# rCSL_usb_otg_001 register map
Vendor: Texas Instruments
Peripheral module from a debugger description file (folder c674x).
Registers are 32-bit, read-write, reset 0x0 unless marked. A register's access mark holds for its fields unless they carry their own. Offsets are as the file gives them; lines under a group give offsets from that group; [hi:lo] are bit positions; {n}, {i} and the like mark numbered series; 'fields as' and 'values as' point back to an identical list; <NAME> marks a mode.

## usb_otg — USB 2.0 OTG Controller with CPPI4.1 DMA Engine
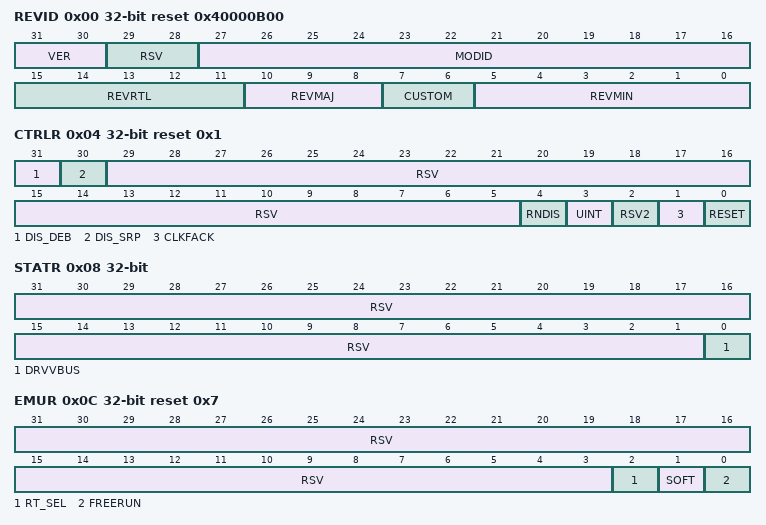
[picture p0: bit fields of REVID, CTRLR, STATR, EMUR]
0x00 REVID ro reset 0x40000B00 (reset mask 0xF000FFFF) — Revision Register
  [31:30] VER — Revision Register Version
  [29:28] RSV — Reserved
  [27:16] MODID — Module ID
  [15:11] REVRTL — RTL Revision
  [10:8] REVMAJ — Major Revision
  [7:6] CUSTOM — Custom Revision
  [5:0] REVMIN — Minor Revision
0x04 CTRLR access per field reset 0x1 — Control Register
  [31] DIS_DEB rw — Disable VBUS Debounce Fix
  [30] DIS_SRP rw — Disable SRP a_valid circuit fix
  [29:5] RSV ro — Reserved
  [4] RNDIS rw — Global RNDIS Mode Enable for All Endpoints
  [3] UINT rw — USB non-PDR Interrupt Enable
  [2] RSV2 ro — Reserved
  [1] CLKFACK rw — Clock Stop Fast Acknowledge
  [0] RESET rw — Soft Reset
0x08 STATR ro — Status Register
  [31:1] RSV — Reserved
  [0] DRVVBUS — Current DRVVBUS Value
0x0C EMUR access per field reset 0x7 — Emulation Register
  [31:3] RSV ro — Reserved
  [2] RT_SEL rw — Real Time Enable
  [1] SOFT rw — Soft Stop Enable
  [0] FREERUN rw — Free Run Enable
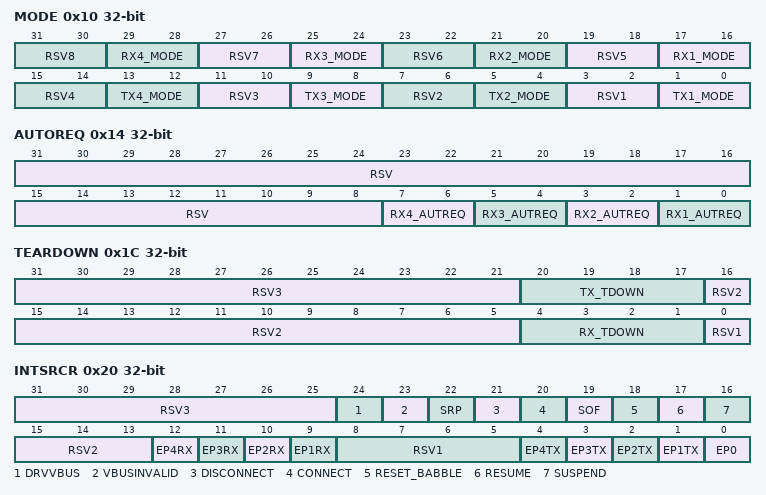
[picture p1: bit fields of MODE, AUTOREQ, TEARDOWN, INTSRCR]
0x10 MODE access per field — RNDIS MODE REGISTER
  [4n-1:4n-2] RSV{n} ro (n=1..8) — Reserved
  [4n+13:4n+12] RX{n}_MODE rw (n=1..4) — RX Endpoint {n} Mode
    0=TRANSPARENT (Transparent Mode); 1=RNDIS (RNDIS Mode); 2=CDC (Linux CDC Mode); 3=GENRNDIS (Generic RNDIS Mode)
  [4n-3:4n-4] TX{n}_MODE rw (n=1..4) — TX Endpoint {n} Mode
    values as RX1_MODE
0x14 AUTOREQ access per field — Auto Request Register
  [31:8] RSV ro — Reserved
  [2n-1:2n-2] RX{n}_AUTREQ rw (n=1..4) — RX{n} Autorequest Enable
    0=NONE (No Auto Req); 1=ALL_BUT_EOP (Auto Req All but EOP); 3=ALL (Auto Req Always)
0x18 SRPFIXTIME reset 0x42000000
  [31:0] SRPFIXTIME — SRP Fix maximum time in 60 MHz cycles. Default is 700ms.
0x1C TEARDOWN access per field
  [31:21] RSV3 ro — Reserved
  [20:17] TX_TDOWN rw — Tx Endpoint Teardown.
    8=TX4 (Teardown TX4 Endpoint); 4=TX3 (Teardown TX3 Endpoint); 2=TX2 (Teardown TX2 Endpoint); 1=TX1 (Teardown TX1 Endpoint)
  [16:5] RSV2 ro — Reserved
  [4:1] RX_TDOWN rw — Rx Endpoint Teardown.
    8=RX4 (Teardown RX4 Endpoint); 4=RX3 (Teardown RX3 Endpoint); 2=RX2 (Teardown RX2 Endpoint); 1=RX1 (Teardown RX1 Endpoint)
  [0] RSV1 ro — Reserved
0x20 INTSRCR ro — USB Interrupt Source Register
  [31:25] RSV3 — Reserved
  [24] DRVVBUS — DRVVBUS Level Change
  [23] VBUSINVALID — VBUS lessthan VBUS Valid
  [22] SRP — SRP Detected
  [21] DISCONNECT — Device Disconnected
  [20] CONNECT — Device Connected
  [19] SOF — SOF Started
  [18] RESET_BABBLE — RESET Signalling Detected (Peripheral Mode) or Babble Detected (Host Mode)
  [17] RESUME — RESUME Signalling Detected
  [16] SUSPEND — SUSPEND Signalling Detected
  [15:13] RSV2 — Reserved
  [n+8] EP{n}RX (n=1..4) — Endpoint {n} RX Interrupt Status
  [8:5] RSV1 — Reserved
  [n] EP{n}TX (n=1..4) — Endpoint {n} TX Interrupt Status
  [0] EP0 — Endpoint 0 Interrupt Status
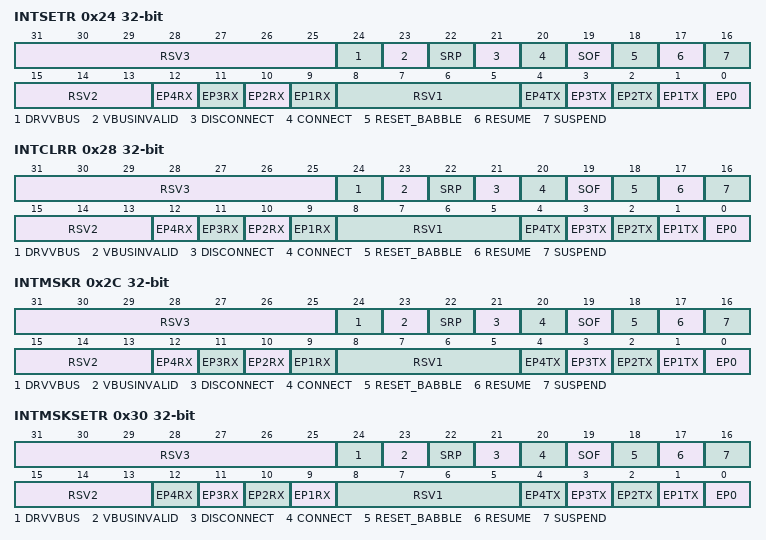
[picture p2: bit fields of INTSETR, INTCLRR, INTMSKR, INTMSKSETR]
0x24 INTSETR access per field — USB Interrupt Source Set Register
  [31:25] RSV3 ro — Reserved
  [24] DRVVBUS wo — DRVVBUS Level Change Interrupt Set
  [23] VBUSINVALID wo — VBUS lessthan VBUS Valid Interrupt Set
  [22] SRP wo — SRP Detected Interrupt Set
  [21] DISCONNECT wo — Device Disconnected Interrupt Set
  [20] CONNECT wo — Device Connected Interrupt Set
  [19] SOF wo — SOF Started Interrupt Set
  [18] RESET_BABBLE wo — RESET Signalling Detected (Peripheral Mode) or Babble Detected (Host Mode) Interrupt Set
  [17] RESUME wo — RESUME Signalling Detected Interrupt Set
  [16] SUSPEND wo — SUSPEND Signalling Detected Interrupt Set
  [15:13] RSV2 ro — Reserved
  [n+8] EP{n}RX wo (n=1..4) — Endpoint {n} RX Interrupt Status Set
  [8:5] RSV1 ro — Reserved
  [n] EP{n}TX wo (n=1..4) — Endpoint {n} TX Interrupt Status Set
  [0] EP0 wo — Endpoint 0 Interrupt Status Set
0x28 INTCLRR access per field — USB Interrupt Source Clear Register
  [31:25] RSV3 ro — Reserved
  [24] DRVVBUS wo — DRVVBUS Level Change Interrupt Set
  [23] VBUSINVALID wo — VBUS lessthan VBUS Valid Interrupt Clear
  [22] SRP wo — SRP Detected Interrupt Clear
  [21] DISCONNECT wo — Device Disconnected Interrupt Clear
  [20] CONNECT wo — Device Connected Interrupt Clear
  [19] SOF wo — SOF Started Interrupt Clear
  [18] RESET_BABBLE wo — RESET Signalling Detected (Peripheral Mode) or Babble Detected (Host Mode) Interrupt Clear
  [17] RESUME wo — RESUME Signalling Detected Interrupt Clear
  [16] SUSPEND wo — SUSPEND Signalling Detected Interrupt Clear
  [15:13] RSV2 ro — Reserved
  [n+8] EP{n}RX wo (n=1..4) — Endpoint {n} RX Interrupt Status Clear
  [8:5] RSV1 ro — Reserved
  [n] EP{n}TX wo (n=1..4) — Endpoint {n} TX Interrupt Status Clear
  [0] EP0 wo — Endpoint 0 Interrupt Status Clear
0x2C INTMSKR ro — USB Interrupt Mask Register
  fields as INTSRCR
0x30 INTMSKSETR access per field — USB Interruppt Mask Set Register
  [31:25] RSV3 ro — Reserved
  [24] DRVVBUS wo — DRVVBUS Level Change Interrupt Mask Set
  [23] VBUSINVALID wo — VBUS lessthan VBUS Valid Interrupt Mask Set
  [22] SRP wo — SRP Detected Interrupt Mask Set
  [21] DISCONNECT wo — Device Disconnected Interrupt Mask Set
  [20] CONNECT wo — Device Connected Interrupt Mask Set
  [19] SOF wo — SOF Started Interrupt Mask Set
  [18] RESET_BABBLE wo — RESET Signalling Detected (Peripheral Mode) or Babble Detected (Host Mode) Interrupt Mask Set
  [17] RESUME wo — RESUME Signalling Detected Interrupt Mask Set
  [16] SUSPEND wo — SUSPEND Signalling Detected Interrupt Mask Set
  [15:13] RSV2 ro — Reserved
  [12] EP4RX wo — Endpoint 4 RX Interrupt Status Mask Set
  [11] EP3RX wo — Endpoint 3 RX Interrupt Mask Set
  [10] EP2RX wo — Endpoint 2 RX Interrupt Mask Set
  [9] EP1RX wo — Endpoint 1 RX Interrupt Mask Set
  [8:5] RSV1 ro — Reserved
  [n] EP{n}TX wo (n=1..4) — Endpoint {n} TX Interrupt Mask Set
  [0] EP0 wo — Endpoint 0 Interrupt Mask Set
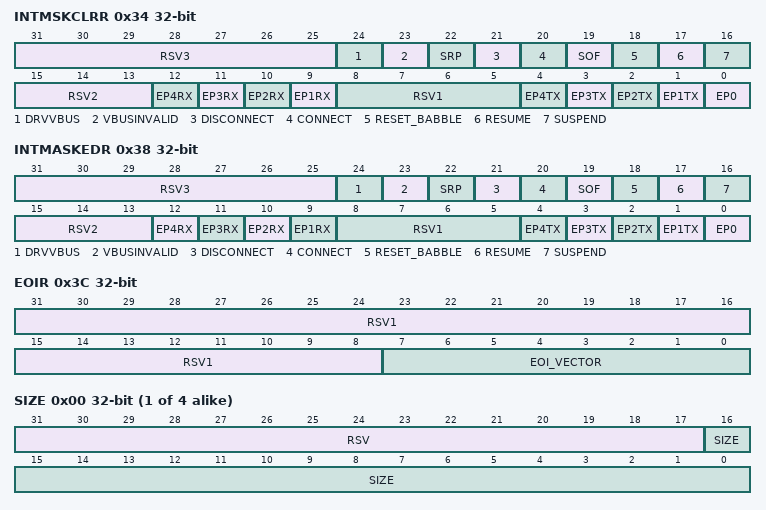
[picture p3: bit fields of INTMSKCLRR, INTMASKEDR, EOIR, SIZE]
0x34 INTMSKCLRR access per field — USB Interruppt Mask Clear Register
  [31:25] RSV3 ro — Reserved
  [24] DRVVBUS wo — DRVVBUS Level Change Interrupt Mask Clear
  [23] VBUSINVALID wo — VBUS lessthan VBUS Valid Interrupt Mask Clear
  [22] SRP wo — SRP Detected Interrupt Mask Clear
  [21] DISCONNECT wo — Device Disconnected Interrupt Mask Clear
  [20] CONNECT wo — Device Connected Interrupt Mask Clear
  [19] SOF wo — SOF Started Interrupt Mask Clear
  [18] RESET_BABBLE wo — RESET Signalling Detected (Peripheral Mode) or Babble Detected (Host Mode) Interrupt Mask Clear
  [17] RESUME wo — RESUME Signalling Detected Interrupt Mask Clear
  [16] SUSPEND wo — SUSPEND Signalling Detected Interrupt Mask Clear
  [15:13] RSV2 ro — Reserved
  [12] EP4RX wo — Endpoint 4 RX Interrupt Status Mask Clear
  [11] EP3RX wo — Endpoint 3 RX Interrupt Mask Clear
  [10] EP2RX wo — Endpoint 2 RX Interrupt Mask Clear
  [9] EP1RX wo — Endpoint 1 RX Interrupt Mask Clear
  [8:5] RSV1 ro — Reserved
  [n] EP{n}TX wo (n=1..4) — Endpoint {n} TX Interrupt Mask Clear
  [0] EP0 wo — Endpoint 0 Interrupt Mask Clear
0x38 INTMASKEDR ro — USB Interrupt Source Masked Register
  fields as INTSRCR
0x3C EOIR access per field — USB End Of Interrupt
  [31:8] RSV1 ro — Reserved
  [7:0] EOI_VECTOR rw
0x40 INTVECTR — USB Interrupt Vector
  [31:0] VECTOR — Interrupt Vector
{0x80+4i} GENRNDISSZ[{i}] (i=0..3) group — RNDIS REGISTERS
  0x00 SIZE access per field — Generic RNDIS Size
    [31:17] RSV ro — Reserved
    [16:0] SIZE rw — Generic RNDIS Packet Size
0x400 FADDR 8-bit — Function Address
  [6:0] FUNCADDR
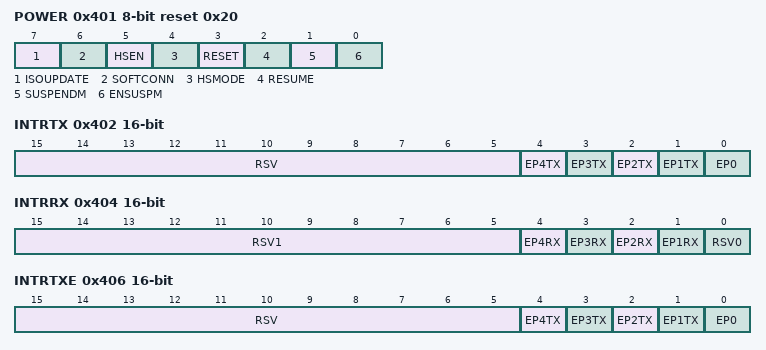
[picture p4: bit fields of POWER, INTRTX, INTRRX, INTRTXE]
0x401 POWER 8-bit access per field reset 0x20 — Power Management Register
  [7] ISOUPDATE rw — Isoc Update
  [6] SOFTCONN rw — Soft Connect/Disconnect - Enables the D+/D- lines when set. Only valid in peripheral mode.
  [5] HSEN rw — When set, the device will negotiate for High speed mode when reset by the hub.
  [4] HSMODE ro — Valid when usb reset completes (peripheral mode) or when Reset bit is cleared (host mode). When set it indicates that the device sucessfully negotiated high speed mode.
  [3] RESET rw — USB Bus Reset: Host mode Read/Write. Peripheral Mode Read Only
  [2] RESUME rw — Set byt the CPU to generate resume signaling when the function is in suspend mode. Automatically set in host mode when Resume signalling from the target is detected and the host is suspended.
  [1] SUSPENDM rw — In host mode, set by the CPU to enter SUSPEND mode. In peripheral mode, this bit is set on entry into SUSPEND mode.
  [0] ENSUSPM rw — Set by the CPU to enable the SUSPENDM signal.
0x402 INTRTX 16-bit ro — Transmit Endpoint Interrupt Register
  [15:5] RSV — Reserved
  [n] EP{n}TX (n=1..4) — EP{n} TX Interrupt
  [0] EP0 — EP0 Interrupt
0x404 INTRRX 16-bit ro — Transmit Endpoint Interrupt Register
  [15:5] RSV1 — Reserved
  [n] EP{n}RX (n=1..4) — EP{n} RX Interrupt
  [0] RSV0 — Reserved
0x406 INTRTXE 16-bit access per field — Transmit Endpoint Interrupt Enable Register
  [15:5] RSV ro — Reserved
  [n] EP{n}TX rw (n=1..4) — EP{n} TX Interrupt
  [0] EP0 rw — EP0 Interrupt
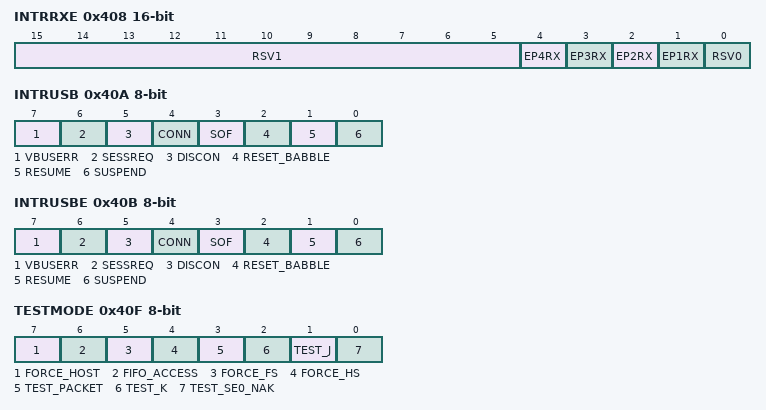
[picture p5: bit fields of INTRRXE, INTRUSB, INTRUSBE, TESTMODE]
0x408 INTRRXE 16-bit access per field — Transmit Endpoint Interrupt Enable Register
  [15:5] RSV1 ro — Reserved
  [n] EP{n}RX rw (n=1..4) — EP{n} RX Interrupt
  [0] RSV0 rw — Reserved
0x40A INTRUSB 8-bit ro — USB Bus Interrupts
  [7] VBUSERR — VBUS lessthan VBUS Valid
  [6] SESSREQ — SRP Detected
  [5] DISCON — Device Disconnected
  [4] CONN — Device Connected
  [3] SOF — SOF Started
  [2] RESET_BABBLE — RESET Signalling Detected (Peripheral Mode) or Babble Detected (Host Mode)
  [1] RESUME — RESUME Signalling Detected
  [0] SUSPEND — SUSPEND Signalling Detected
0x40B INTRUSBE 8-bit — USB Interrupt Enable Register
  fields as INTRUSB
0x40C FRAME 16-bit ro — Frame Number of Last Received Frame
  [10:0] FRAMENUMBER
0x40E INDEX 8-bit — Selects Endpoint accessed through index register
  [3:0] EPSEL — Endpoint Selection Index
    0=EP0; {v}=EP{v} (v=0..4)
0x40F TESTMODE 8-bit
  [7] FORCE_HOST, [6] FIFO_ACCESS, [5] FORCE_FS, [4] FORCE_HS, [3] TEST_PACKET, [2] TEST_K, [1] TEST_J, [0] TEST_SE0_NAK
0x410 TXMAXP 16-bit — Max Packet Size for Transmit Packet
  [10:0] MAXPAYLOAD
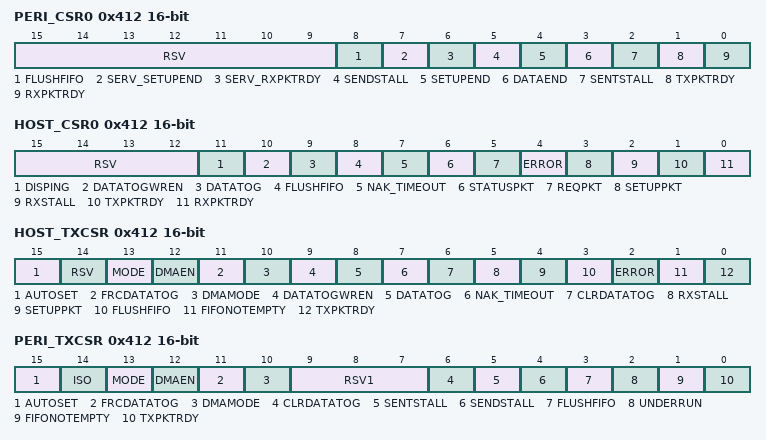
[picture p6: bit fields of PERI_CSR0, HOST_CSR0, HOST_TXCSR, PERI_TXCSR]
0x412 PERI_CSR0 16-bit access per field — TRANSMIT / ENDPOINT 0 CONTROL AND STATUS IN PERIPHERAL MODE
  [15:9] RSV ro — Reserved
  [8] FLUSHFIFO rw — Write a 1 to this bit to flush the enxt packet to be transmitted/read from the Endpoint0 FIFO. The FIFO pointer is reset and the TXPKTRDY/RXPKTRDY bit is cleared.
  [7] SERV_SETUPEND rw — Write 1 to Clear SetupEnd bit.
  [6] SERV_RXPKTRDY rw — Write 1 to clear RXPKTRDY bit.
  [5] SENDSTALL rw — Write 1 to terminate the current transaction
  [4] SETUPEND rw — This bit will be set when a control transaction ends before the DataEnd bit has been set. An interrupt will be generated and the FIFO flushed at this time. The bit is cleared by the CPU writing a 1 to the SERVICED_SETUP_END bit
  [3] DATAEND rw
  [2] SENTSTALL rw — This bit is set when a STALL handshake is transmitted. The CPU should clear this bit
  [1] TXPKTRDY rw — The CPU sets this bit after loading a data packet into the FIFO. It is cleared automatically when the data packet has been transmitted. An interrupt is generated (if enabled) when this bit is cleared.
  [0] RXPKTRDY rw — This bit is set when a data packet has been received. An interrupt is generated when this bit is set. The CPU clears this bit by setting the SERVICED_RXPKTRDY bit.
0x412 HOST_CSR0 16-bit access per field — TRANSMIT / ENDPOINT 0 CONTROL AND STATUS IN HOST MODE
  [15:12] RSV ro — Reserved
  [11] DISPING rw — The CPU writes a 1 to this bit to instruct the core not to issue PING tokens in data and status phases of a high-speed Control transfer (For use with devices that do not respond to PING)
  [10] DATATOGWREN rw — The CPU writes a 1 to this bit to enable the current state of the Endpoint 0 data toggle to be written. This bit is automatically cleared once the new value is written.
  [9] DATATOG rw — When read, this bit indicates the current state of the Endpoint 0 data toggle. If D10 is high, this bit may bw written with the required setting of the data toggle. If D10 is low, any value written to this bit is ignored.
  [8] FLUSHFIFO rw — The CPU writes a 1 to this bit to flush the next packet to be transmitted/read from the Endpoint 0 FIFO. The FIFO pointer is reset and the TXPKTRDY/RXPKTRDY bit(Below) is cleared. Note: FlushFIFO should only be used when TXPKTRDY/RXPKTRDY is SET. At other times it may cause data to be corrupted.
  [7] NAK_TIMEOUT rw — This bit will be set when Endpoint 0 is halted following the receipt of NAK responses for longer than the time set by the NAKLimit0 register. The CPU should clear this bit to allow the endpoint to continue.
  [6] STATUSPKT rw — The CPU sets this bit at the same time as the TXPKTRDY or REQPKT bit is set, to perform a status stage transaction. Setting this bit ensures that the data toggle is set to 1 so that a DATA1 packet is used for the Status Stage transaction.
  [5] REQPKT rw — The CPU sets this bit to request an IN transaction. It is cleared when the RXPKTRDY is set.
  [4] ERROR rw — This bit will be set when a control transaction ends before the DataEnd bit has been set. An interrupt will be generated and the FIFO flushed at this time. The bit is cleared by the CPU writing a 1 to the SERVICED_SETUP_END bit
  [3] SETUPPKT rw — The CPU sets this bit, at the same time as the TXPKTRDY bit is set to send a SETUP token instead of an OUT token for the transaction. Note: Setting this bit also clears the data toggle.
  [2] RXSTALL rw — This bit is set when a STALL handshake is received. The CPU should clear this bit
  [1] TXPKTRDY rw — The CPU sets this bit after loading a data packet into the FIFO. It is cleared automatically when the data packet has been transmitted. An interrupt is generated (if enabled) when this bit is cleared.
  [0] RXPKTRDY rw — This bit is set when a data packet has been received. An interrupt is generated when this bit is set. The CPU clears this bit by setting the SERVICED_RXPKTRDY bit.
0x412 HOST_TXCSR 16-bit access per field — CSR REGISTER FOR TRANSMIT ENDPOINT (INDEXED) - HOST MODE
  [15] AUTOSET rw — If the CPU sets this bit, TXPKTRDY will be automatically set when data of the maximum packet size (Value in TXMAXP) is loaded into the TX FIFO. If a packet of less than the maximum packet size is loaded, then TXPKTRDY will have to be set manually.
  [14] RSV ro — RESERVED - RETURNS 0
  [13] MODE rw — The CPU sets this bit to enable the endpoint direction as TX and clears it to enable the endpoint direction as RX. Only takes effect when the same endpoint FIFO is used for both TX and RX transactions
  [12] DMAEN rw — The CPU sets this bit to enable the DMA request for the TX Endpoint
  [11] FRCDATATOG ro — Reserved
  [10] DMAMODE ro
  [9] DATATOGWREN ro — Reserved
  [8] DATATOG ro — Reserved
  [7] NAK_TIMEOUT ro — Reserved
  [6] CLRDATATOG rw — The CPU writes a 1 to this bit to reset the endpoint data toggle to 0
  [5] RXSTALL rw — This bit is set when a STALL handshake is received. When this bit is set, any DMA request that is in progress is stopped, the FIFO is completely flushed, and the TXPKTRDY bit is cleared. The CPU should clear this bit.
  [4] SETUPPKT rw — The CPU sets this bit, at the same time as the TXPKTRDY bit is set, to send a SETUP token instead of an OUT token for the transaction. Note: Setting this bit also clears the Data Toggle.
  [3] FLUSHFIFO rw — The CPU writes a 1 to this bit to flush the latest packet from the endpoint TX FIFO. The FIFO pointer is reset, the TXPKTRDY bit is cleared and an interrupt is generated. May be set simultanelusly with TXPKTRDY to abort the packet that is currently being loaded into the FIFO. Note: Flush FIFO shoudl onlyb e used when TXPKTRDY is set. At other times, it may cause data to be corrupted. Also note that, if the FIFO is doubled buffered, FLUSH_FIFO may need to be set twice to compltetely clear the FIFO
  [2] ERROR rw — The USB sets this bit when 3 attempts have been made to send a packet and no handshake packet has been received. When the bit is set, and interrupt is generated, TXPKTRDY is cleared, and the FIFO is completely flushed. The CPU should clear this bit. Valid only when the endpoint is operating in Bulk or Interrupt Mode.
  [1] FIFONOTEMPTY rw — The USB sets this bit when there is at least 1 packet in the TX FIFO
  [0] TXPKTRDY rw — The CPU sets this bit after loading a data packet into the FIFO. It is cleared automatically when a data packet has been transmitted. An interrupt is also generated at thsi point (if enabled) TXPKTRDY is also automatically cleared prior to loading a second packet into a double-buffered FIFO
0x412 PERI_TXCSR 16-bit access per field — CSR REGISTER FOR TRANSMIT ENDPOINT (INDEXED) - PERIPHERAL MODE
  [15] AUTOSET rw — If the CPU sets this bit, TXPKTRDY will be automatically set when data of the maximum packet size (Value in TXMAXP) is loaded into the TX FIFO. If a packet of less than the maximum packet size is loaded, then TXPKTRDY will have to be set manually.
  [14] ISO rw — CPU sets this bit to enable the TX Endpoint for Isochronous Transfers, and clears it to enable the TX Endpoint for Bulk or Interrupt Transfers.
  [13] MODE rw — The CPU sets this bit to enable the endpoint direction as TX and clears it to enable the endpoint direction as RX. Only takes effect when the same endpoint FIFO is used for both TX and RX transactions
  [12] DMAEN rw — The CPU sets this bit to enable the DMA request for the TX Endpoint
  [11] FRCDATATOG rw
  [10] DMAMODE rw
  [9:7] RSV1 ro — Reserved
  [6] CLRDATATOG rw — The CPU writes a 1 to this bit to reset the endpoint data toggle to 0
  [5] SENTSTALL rw — This bit is set when a STALL handshake is transmitted. The FIFO is flushed and the TXPKTRDY bit is cleared.
  [4] SENDSTALL rw — The CPU writes a 1 to this bit to issue a STALL handshake to an IN token. The CPU clears this bit to terminate a stall condition
  [3] FLUSHFIFO rw — The CPU writes a 1 to this bit to flush the latest packet from the endpoint TX FIFO. The FIFO pointer is reset, the TXPKTRDY bit is cleared and an interrupt is generated. May be set simultanelusly with TXPKTRDY to abort the packet that is currently being loaded into the FIFO. Note: Flush FIFO shoudl onlyb e used when TXPKTRDY is set. At other times, it may cause data to be corrupted. Also note that, if the FIFO is doubled buffered, FLUSH_FIFO may need to be set twice to compltetely clear the FIFO
  [2] UNDERRUN rw — The USB sets this bit if an IN token is received when the TXPKTRDY bit is not set. The CPU should clear this bit.
  [1] FIFONOTEMPTY rw — The USB sets this bit when there is at least 1 packet in the TX FIFO
  [0] TXPKTRDY rw — The CPU sets this bit after loading a data packet into the FIFO. It is cleared automatically when a data packet has been transmitted. An interrupt is also generated at thsi point (if enabled) TXPKTRDY is also automatically cleared prior to loading a second packet into a double-buffered FIFO
0x414 RXMAXP 16-bit — RX ENDPOINT MAX PACKET SIZE
  [10:0] MAXPAYLOAD
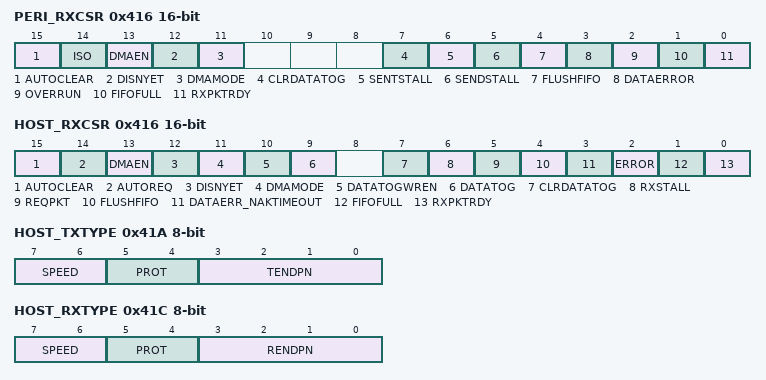
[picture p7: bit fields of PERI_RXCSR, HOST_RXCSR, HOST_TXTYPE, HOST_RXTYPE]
0x416 PERI_RXCSR 16-bit — Receive Control/Status Register Peripheral Mode
  [15] AUTOCLEAR — If the CPU sets this bit then the RXPKTRDY bit will be automatically cleared when a packet of RXMAXP bytes has been unloaded from the RXFIFO. When packets of less than the maximum packet size are unloaded. RXPKTRDY will have to be cleared manually.
  [14] ISO — The CPU sets this bit to enable the RX Endpoint for ISOCHRONOUS transfers and clears it to enable the RX Endpoint for Bulk/Interrupt transfers
  [13] DMAEN — The CPU sets this bit to enable the DMA request for the RX Endpoint
  [12] DISNYET — In bulk and interrupt mode, the CPU sets this bit to disable the sending of a NYET handshake. When set all sucessfully received RX packets are ACK'd including at the point at which the FIFO becomes ful.
  [11] DMAMODE — The CPU sets thsi bit to select DMA Mode 1 and clears this bit to select DMA Mode 0
  [7] CLRDATATOG — The CPU writes a 1 to this bit to reset the endpoint data toggle to 0
  [6] SENTSTALL — This bit is set when a STALL handshake is transmitted. The CPU should clear this bit.
  [5] SENDSTALL — The CPU writes a 1 to this bit to issue a STALL handshake. The CPU clears this bit to terminate the stall condition.
  [4] FLUSHFIFO — The CPU writes a 1 to this bit to flush the next packet to be read from the Endpoint RX FIFO. The FIFO pointer is reset and the RXPKTRDY bit is cleared. Note that if the FIFO is doubled buffered, FIFOFLUSH may need to be set twice to completely clear the FIFO
  [3] DATAERROR — This bit is set if the data packet has a CRC or bit-stuff error. It is cleared when RXPKTRDY is cleared.
  [2] OVERRUN — This bit is set if an OUT packet cannot be loaded into the RX FIFO. THe CPU should clear this bit.
  [1] FIFOFULL — This bit is set when no more packets can be loaded into the RX FIFO
  [0] RXPKTRDY — This bit is set when a data packet has been received. The CPU should clear this bit when the packet has been unloaded from the RX FIFO. An interrupt is generated when the bit is set.
0x416 HOST_RXCSR 16-bit access per field — Receive Control/Status Register Host Mode
  [15] AUTOCLEAR rw — If the CPU sets this bit then the RXPKTRDY bit will be automatically cleared when a packet of RXMAXP bytes has been unloaded from the RXFIFO. When packets of less than the maximum packet size are unloaded. RXPKTRDY will have to be cleared manually.
  [14] AUTOREQ rw — If the CPU sets this bit, the ReqPkt bit will be automatically set when the RXPKTRDY bit is cleared. Note: This bit is automatically cleared when a short packet is received.
  [13] DMAEN rw — The CPU sets this bit to enable the DMA request for the RX Endpoint
  [12] DISNYET rw — ISO TRANSACTIONS ONLY: The core sets this bit to indicate a PID error in the received packet. Ignored in Bulk/Interrupt Transactions.
  [11] DMAMODE rw — The CPU sets this bit to select DMA Mode 1 and clears this bit to select DMA Mode 0
  [10] DATATOGWREN ro — The CPU writes a 1 to this bit to enable the current state of the RX Endpoint Data toggle to be written. This bit is automatically cleared once the new value is written.
  [9] DATATOG ro — When read, this bit indicates the current state of the RX Endpoint Data Toggle. If DATA_TOGGLE_WRITE_ENABLE is '1' then this bit may be written with the required setting of the data toggle. If DATA_TOGGLE_WRITE_ENABLE is low, any value written to this register is ignored.
  [7] CLRDATATOG rw — The CPU writes a 1 to this bit to reset the endpoint data toggle to 0
  [6] RXSTALL rw — When a STALL handshake is received, this bit is set and an interrupt is generated. The CPU should clear this bit.
  [5] REQPKT rw — The CPU writes a 1 to this bit to request an IN transaction. It is cleared when RXPKTRDY is set
  [4] FLUSHFIFO rw — The CPU writes a 1 to this bit to flush the next packet to be read from the Endpoint RX FIFO. The FIFO pointer is reset and the RXPKTRDY bit is cleared. Note that if the FIFO is doubled buffered, FIFOFLUSH may need to be set twice to completely clear the FIFO
  [3] DATAERR_NAKTIMEOUT rw — When operating in ISO mode, this bit is set when RXPKTRDY is set if the data packet has a CRC or bit-stuff error and cleared when the RXPKTRDY is cleared. In bulk mode, this bit will be set when the RX endpoint is halted following the receipt of NAK responses for longer than the time set as the NAK Limit by the RxInterval register. The CPU should celar this bit to allow the endpoint to continue.
  [2] ERROR rw — The USB sets this bit when 3 attempts have been made to receive a packet and no data packet has been received. The CPU should clear this bit. An interrupt is generated when the bit is set. Note: thsi bit is only valid when the TX endpoint is operating in Bulk or Interrupt mode. In ISO mode, it always returns 0
  [1] FIFOFULL rw — This bit is set when no more packets can be loaded into the RX FIFO
  [0] RXPKTRDY rw — This bit is set when a data packet has been received. The CPU should clear this bit when the packet has been unloaded from the RX FIFO. An interrupt is generated when the bit is set.
0x418 COUNT0 16-bit ro — Count0 is a 7 bit read only register that indicates the number of received data bytes in the Endpoint 0 FIFO. The value returned changes as the contents of the FIFO change and is only valid while RXPKTRDY is set.
  [6:0] EP0RXCOUNT
0x418 RXCOUNT 16-bit ro — RX Count is a 13-bit read only register that holds the number of received dtata bytes in the packet currently in line to be read from the RX FIFO. If the packet was transmitted as multiple bulk packets, the number given will be for the combined packet.
  [12:0] EPRXCOUNT
0x41A HOST_TYPE0 8-bit — TYPE0 FOR ENDPOINT 0
  [7:6] SPEED
    1=HS (High Speed); 2=FS (Full Speed); 3=LS (Low Speed)
0x41A HOST_TXTYPE 8-bit — TXTYPE FOR ENDPOINT1,2,3,4
  [7:6] SPEED
    1=HS (High Speed); 2=FS (Full Speed); 3=LS (Low Speed)
  [5:4] PROT
    0=CTRL (Control); 1=ISOC (Isochronous); 2=BULK; 3=INTR (Interrupt)
  [3:0] TENDPN
0x41B HOST_NAKLIMIT0 8-bit — NAKLIMIT0 FOR ENDPOINT 0
  [4:0] EP0NAKLIMIT
0x41B HOST_TXINTERVAL 8-bit — TXINTERVAL FOR ENDPOINT1,2,3,4
  [7:0] POLINTVL_NAKLIMIT
0x41C HOST_RXTYPE 8-bit — RXTYPE FOR ENDPOINT1,2,3,4
  [7:6] SPEED
    1=HS (High Speed); 2=FS (Full Speed); 3=LS (Low Speed)
  [5:4] PROT
    values as HOST_TXTYPE.PROT
  [3:0] RENDPN
0x41D HOST_RXINTERVAL 8-bit — RXINTERVAL FOR ENDPOINT1,2,3,4
  [7:0] POLINTVL_NAKLIMIT
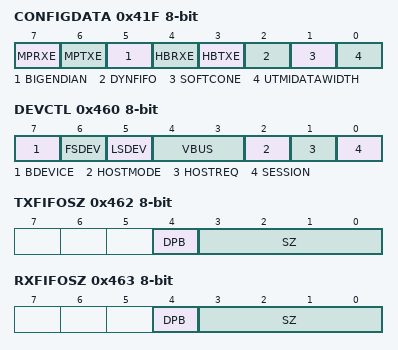
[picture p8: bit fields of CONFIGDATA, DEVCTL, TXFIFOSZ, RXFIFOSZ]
0x41F CONFIGDATA 8-bit ro — Returns details of core configuration for Endpoint 0
  [7] MPRXE — When set to '1' automatic almagamation of bulk packets is selected
  [6] MPTXE — When set to '1' automatic splitting of bulk packets is selected
  [5] BIGENDIAN — When set to '1' Big Endian ordering is selected
  [4] HBRXE — When set to '1' indicates High Badnwidth RX FIFO ISO endpoint support selected
  [3] HBTXE — When set to '1' indicates High Badnwidth TX FIFO ISO endpoint support selected
  [2] DYNFIFO — When set to '1' indicates Dynamic FIFO Sizing option is selected
  [1] SOFTCONE — When set to '1' indicates Soft Connect / Disconnect Option Selected
  [0] UTMIDATAWIDTH — Indicates UTMI+ data width. 0 - 8 bits, 1 - 16 bits
{0x420+4i} FIFO{i} (i=0..4)
  [31:0] DATA — FIFO Data
0x460 DEVCTL 8-bit access per field — OTG Device Control
  [7] BDEVICE ro — THIS READ ONLY BIT INDICATES WHETHER THE DEVICE IS OPERATING AS THE a OR THE b DEVICE.
    0=ADEV (A DEVICE); 1=BDEV (B DEVICE)
  [6] FSDEV ro — THIS READ ONLY BIT INDICATES WHETHER THE DEVICE IS OPERATING IN FULL SPEED OR HIGH SPEED. ONLY VALID IN HOST MODE
    0=HS (high speed); 1=FS (full speed)
  [5] LSDEV ro — THIS READ ONLY BIT INDICATES WHETHER THE DEVICE IS OPERATING IN LOW SPEED. ONLY VALID IN HOST MODE
    0=FS (full speed); 1=LS (low speed)
  [4:3] VBUS ro — THESE READ ONLY BITS ENCODE THE CURRENT VBUS LEVEL
    0=BELOW_SESSION_END (VBUS is below the session End Level); 1=BELOW_AVALID (VBUS is above session End but below AVALID); 2=BELOW_VBUS_VALID (VBUS is above AVALID, but below VBUS Valid); 3=ABOVE_VBUS_VALID (VBUS is above VBUS Valid)
  [2] HOSTMODE ro — This read only bit is set when the USB controller is acting as a HOST
    0=PER_MODE (Peripheral Mode); 1=HOST_MODE
  [1] HOSTREQ rw — When set, the controller will initiate the Host Negotiation Protocol when Suspend mode is entered. It is cleared when Host Negotiation is completed.
    0=HNP_END (HNP Completed); 1=START_HNP (Start Host Negotiation On Suspend Entry)
  [0] SESSION ro — When acting as an "A" device, this bit is set or cleared by the CPU to start or end a session. When operating as a 'b' device, this bit is set/cleared by the controller when a session starts/ends. It is also set by the CPU to initiate the Session Request Protocol. When the controller is in suspend mode the bit may be cleared by the CPU to perform a software disconnect. Note: Clearing this bit when the core is not suspended will result in undefined behavior
    0=SESSION_END (End Session); 1=SESSION_START (Start Session)
0x462 TXFIFOSZ 8-bit — TRANSMIT ENDPOINT FIFO SIZE (INDEXED)
  [4] DPB — Double Packet Buffering Supported When Set
    0=DISABLE; 1=ENABLE
  [3:0] SZ — Reserved
    0=8_BYTES (8 Byte FIFO Size); 1=16_BYTES (16 Byte FIFO Size); 2=32_BYTES (32 Byte FIFO Size); 3=64_BYTES (64 Byte FIFO Size); 4=128_BYTES (128 Byte FIFO Size); 5=256_BYTES (256 Byte FIFO Size); 6=512_BYTES (512 Byte FIFO Size); 7=1024_BYTES (1024 Byte FIFO Size); 8=2048_BYTES (2048 Byte FIFO Size); 9=4096_BYTES (4096 Byte FIFO Size)
0x463 RXFIFOSZ 8-bit access per field — RECEIVE ENDPOINT FIFO SIZE (INDEXED)
  [4] DPB ro — Double Packet Buffering Supported When Set
    0=DISABLE; 1=ENABLE
  [3:0] SZ rw — FIFO SIZE
    values as TXFIFOSZ.SZ
0x464 TXFIFOADDR 16-bit — TRANSMIT ENDPOINT FIFO ADDRESS - IN UNITS OF 8 BYTES (INDEXED)
  [12:0] ADDR — FIFO Address
0x466 RXFIFOADDR 16-bit — RECEIVE ENDPOINT FIFO ADDRESS - IN UNITS OF 8 BYTES (INDEXED)
  [12:0] ADDR — FIFO Address
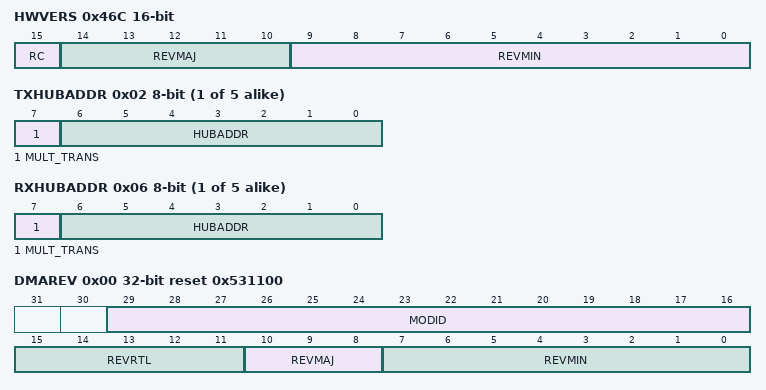
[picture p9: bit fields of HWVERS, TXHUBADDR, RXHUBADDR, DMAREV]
0x46C HWVERS 16-bit ro — VERSION OF USB CONTROLLER CORE
  [15] RC, [14:10] REVMAJ, [9:0] REVMIN
{0x480+8i} EPTRG[{i}] (i=0..4) group — ENDPOINT FUNCTION ADDRESS REGISTERS
  0x00 TXFUNCADDR 8-bit — transmit endpoint function address (host mode only)
    [6:0] FUNCADDR — FIFO Address
  0x02 TXHUBADDR 8-bit — transmit endpoint hub address (host mode only)
    [7] MULT_TRANS — Reserved
    [6:0] HUBADDR — Reserved
  0x03 TXHUBPORT 8-bit — transmit endpoint hub port (host mode only)
    [6:0] HUBPORT
  0x04 RXFUNCADDR 8-bit — receive endpoint function address (host mode only)
    [6:0] FUNCADDR — FIFO Address
  0x06 RXHUBADDR 8-bit — receive endpoint hub address (host mode only)
    [7] MULT_TRANS — Reserved
    [6:0] HUBADDR — Reserved
  0x07 RXHUBPORT 8-bit — receive endpoint hub port (host mode only)
    [6:0] HUBPORT
{0x500+0x10*i} EPCSR[{i}] (i=0..4) group — ENDPOINT CONTROL AND STATUS REGISTERS
  0x00 TXMAXP 16-bit access not given reset not defined — Max Packet Size for Transmit Packet
  0x02 PERI_CSR0 16-bit access not given reset not defined — TRANSMIT / ENDPOINT 0 CONTROL AND STATUS IN PERIPHERAL MODE
  0x04 RXMAXP 16-bit access not given reset not defined — RX ENDPOINT MAX PACKET SIZE
  0x06 PERI_RXCSR 16-bit access not given reset not defined — Receive Control/Status Register Peripheral Mode
  0x08 COUNT0 16-bit access not given reset not defined — Count0 is a 7 bit read only register that indicates the number of received data bytes in the Endpoint 0 FIFO. The value returned changes as the contents of the FIFO change and is only valid while RXPKTRDY is set.
  0x0A HOST_TYPE0 8-bit access not given reset not defined — TYPE0 FOR ENDPOINT 0
  0x0B HOST_NAKLIMIT0 8-bit access not given reset not defined — NAKLIMIT0 FOR ENDPOINT 0
  0x0C HOST_RXTYPE 8-bit access not given reset not defined — RXTYPE FOR ENDPOINT1,2,3,4
  0x0D HOST_RXINTERVAL 8-bit access not given reset not defined — RXINTERVAL FOR ENDPOINT1,2,3,4
  0x0F CONFIGDATA 8-bit access not given reset not defined — Returns details of core configuration for Endpoint 0
{0x700+2i} RQPKTCOUNT[{i}] (i=0..3) group — NUMBER OF REQUESTED PACKETS FOR ENDPOINTS 1 THROUGH 4
  0x00 RQPKTCOUNT 16-bit access not given reset not defined — Number of requested packets for Receive Endpoint
0x1000 DMA_GLOBAL group — USB CPPI4.1 DMA
  0x00 DMAREV ro reset 0x531100 — CDMA REVISION REGISTER
    [29:16] MODID — Module ID
    [15:11] REVRTL — RTL revision
    [10:8] REVMAJ — Major revision
    [7:0] REVMIN — Minor revision
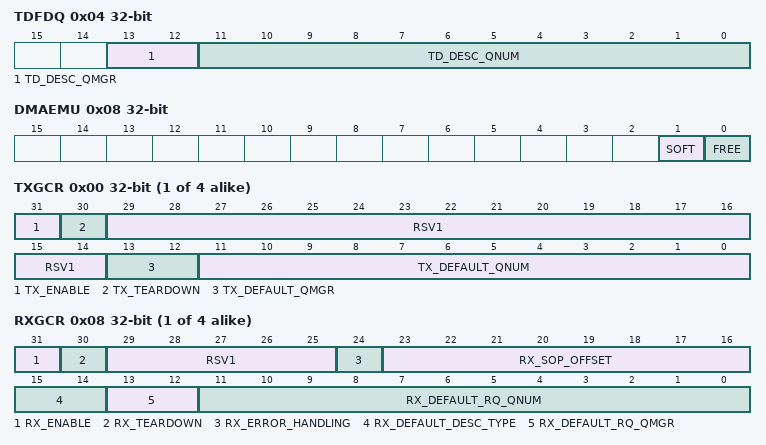
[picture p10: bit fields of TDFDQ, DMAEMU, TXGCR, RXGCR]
  0x04 TDFDQ — Tear Down Free Descriptor queue register. Informs the DMA of the location in memory which is to be used for signalling of a teardown complete for each TX and RX channel.
    [13:12] TD_DESC_QMGR — Controls which 4 queue manager the DMA access
    [11:0] TD_DESC_QNUM — Controls which queue should be read to allocate the TD descriptors
  0x08 DMAEMU — Emulation Control Register
    [1] SOFT, [0] FREE
{0x1800+0x20*i} DMA_CTRL[{i}] (i=0..3) group — Global Control Registers
  0x00 TXGCR access per field — Transmit DMA Global Control Register
    [31] TX_ENABLE rw — This field enables or disables the channel.
    [30] TX_TEARDOWN rw — Setting this bit will request the channel to be torn down. This field will remain set after a channel teardown is complete.
    [29:14] RSV1 rw — Setting this bit will request the channel to be torn down. This field will remain set after a channel teardown is complete.
    [13:12] TX_DEFAULT_QMGR wo — This field controls the default queue manager number that will be used to queue teardown descriptors back to the host
    [11:0] TX_DEFAULT_QNUM wo — This field controls the default queue number within the selected queue manager onto which teardown descriptors will be queued back to the host.
  0x08 RXGCR access per field — Receive DMA Global Control Register
    [31] RX_ENABLE rw — This field enables or disables the channel.
    [30] RX_TEARDOWN rw — Setting this bit will request the channel to be torn down. This field will remain set after a channel teardown is complete.
    [29:25] RSV1 ro — Reserved
    [24] RX_ERROR_HANDLING wo — This bit controls the error handling mode for the channel
      0=DROP (Starvation errors result in returning any allocated descriptor/buffer resources and then dropping the packet.); 1=RETRY (Starvation errors result in retrying RX Descriptor/Buffer allocation until successful)
    [23:16] RX_SOP_OFFSET wo — This field specifies the number of bytes that are to be skipped in the SOP buffer before beginning to write the payload. This value must be less than the minimum size of a buffer in the system. Valid values are 0-255 bytes. This value is only used for host and embedded descriptor types.
    [15:14] RX_DEFAULT_DESC_TYPE wo — This field indicates the default descriptor type to use
      0=EMBEDDED; 1=HOST; 2=MONOLITHIC
    [13:12] RX_DEFAULT_RQ_QMGR wo — This field indicates the default receive queue manager that this channel should use. The actual receive queue manager index can be overridden by information provided in the CPPI FIFO data block
    [11:0] RX_DEFAULT_RQ_QNUM wo — This field indicates the default receive queue that this channel should use. The actual receive queue that will be used for reception can be overridden by information provided in the CPPI FIFO data block
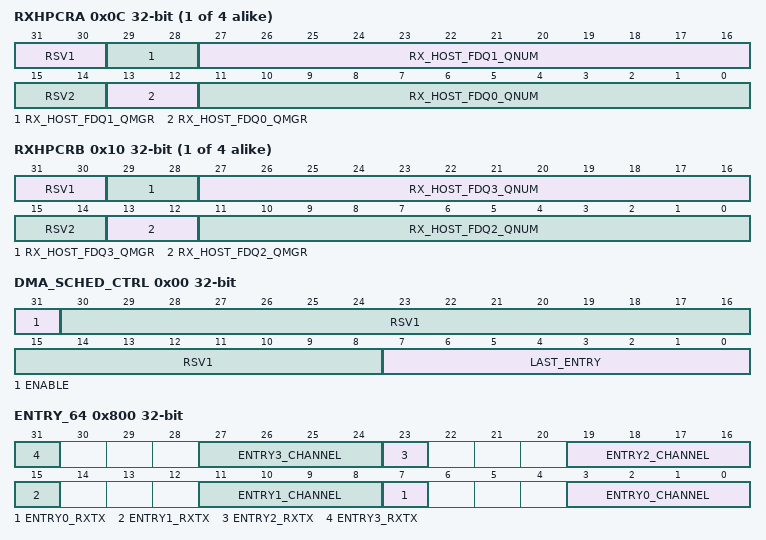
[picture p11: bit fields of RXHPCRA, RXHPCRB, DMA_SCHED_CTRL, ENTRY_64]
  0x0C RXHPCRA access per field — Receive DMA Host Packet Configuration Register
    [31:30] RSV1 ro — Reserved
    [29:28] RX_HOST_FDQ1_QMGR wo — This field specifies which buffer manager should be used for the 2nd RX buffer in a host type packet
    [27:16] RX_HOST_FDQ1_QNUM wo — This field specifies which free descriptor/buffer pool should be used for the 2nd RX buffer in a host type packet
    [15:14] RSV2 ro — Reserved
    [13:12] RX_HOST_FDQ0_QMGR wo — This field specifies which buffer manager should be used for the 1st RX buffer in a host type packet
    [11:0] RX_HOST_FDQ0_QNUM wo — This field specifies which free descriptor/buffer pool should be used for the 1st RX buffer in a host type packet
  0x10 RXHPCRB access per field — Receive DMA Host Packet Configuration Register B
    [31:30] RSV1 ro — Reserved
    [29:28] RX_HOST_FDQ3_QMGR wo — This field specifies which buffer manager should be used for the 4th RX buffer in a host type packet
    [27:16] RX_HOST_FDQ3_QNUM wo — This field specifies which free descriptor/buffer pool should be used for the 4th RX buffer in a host type packet
    [15:14] RSV2 ro — Reserved
    [13:12] RX_HOST_FDQ2_QMGR wo — This field specifies which buffer manager should be used for the 3rd RX buffer in a host type packet
    [11:0] RX_HOST_FDQ2_QNUM wo — This field specifies which free descriptor/buffer pool should be used for the 3rd RX buffer in a host type packet
0x2000 DMA_SCHED group — Global Control Registers
  0x00 DMA_SCHED_CTRL access per field — Receive DMA Host Packet Configuration Register B Endpoint 4
    [31] ENABLE rw — Enable bit for Scheduler
      0=DISABLE (Scheduler is disabled and will no longer fetch entries from the scheduler table or pass credits to the DMA controller); 1=ENABLE (Scheduler is enabled. This bit should only be set after the table has been initialized)
    [30:8] RSV1 ro — Reserved
    [7:0] LAST_ENTRY rw — This field indicates the last valid entry in the scheduler table. There are 64 words in the table and there are 4 entries in each word. The table can be programmed with any integer number of entries from 1 to 256.
  0x800 ENTRY_64 wo — DMA Scheduler Table Entry
    [8n+7] ENTRY{n}_RXTX (n=0..3)
      0=TX (TX Channel); 1=RX (RX Channel)
    [8n+3:8n] ENTRY{n}_CHANNEL (n=0..3) — Channel Number
      {v}=CHAN{v} (CHANNEL {v}) (v=0..3)
0x4000 QMGR group — Queue Manager Control Registers
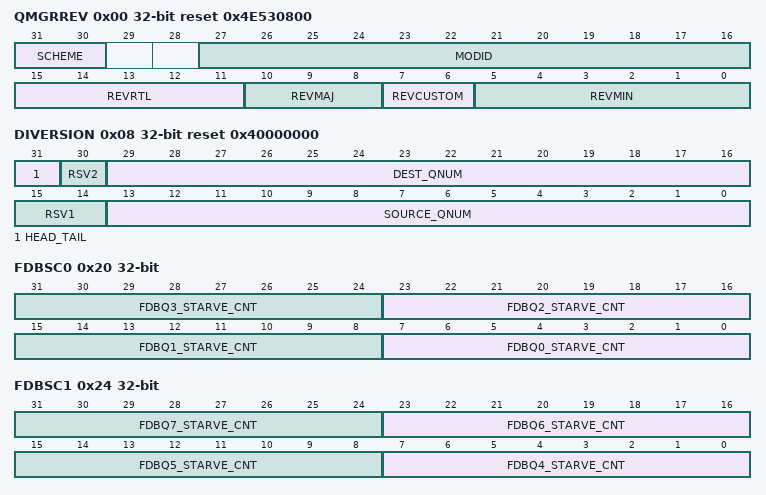
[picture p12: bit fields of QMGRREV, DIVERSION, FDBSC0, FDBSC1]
  0x00 QMGRREV ro reset 0x4E530800 — Queue Manager Revision Register
    [31:30] SCHEME
    [27:16] MODID — MODULE ID FIELD
    [15:11] REVRTL — RTL Revision
    [10:8] REVMAJ — Major Revision
    [7:6] REVCUSTOM — Custom Revision
    [5:0] REVMIN — Minor Revision
  0x08 DIVERSION access per field reset 0x40000000 (reset mask 0xFFFF3FFF) — Queue Manager Diversion Register
    [31] HEAD_TAIL wo — HEAD TAIL Push Control. Set to zero to push packet to tail of queue and one to push packet to head of queue
      0=TAILINS (Insert packet to tail of queue); 1=HEADINS (Insert packet to head of queue)
    [30] RSV2 ro — Reserved
    [29:16] DEST_QNUM ro — Destination Queue Number
    [15:14] RSV1 ro — Reserved
    [13:0] SOURCE_QNUM ro — Source Queue Number
  0x20 FDBSC0 ro — Queue Manager Free Descriptor/Buffer Starvation Count Register 0
    [8n+7:8n] FDBQ{n}_STARVE_CNT (n=0..3) — This field increments each time Free Descriptor/Buffer Read Queue {n} is read while empty. This field is cleared on read.
  0x24 FDBSC1 ro — Queue Manager Free Descriptor/Buffer Starvation Count Register 1
    [8n-25:8n-32] FDBQ{n}_STARVE_CNT (n=4..7) — This field increments each time Free Descriptor/Buffer Read Queue {n} is read while empty. This field is cleared on read.
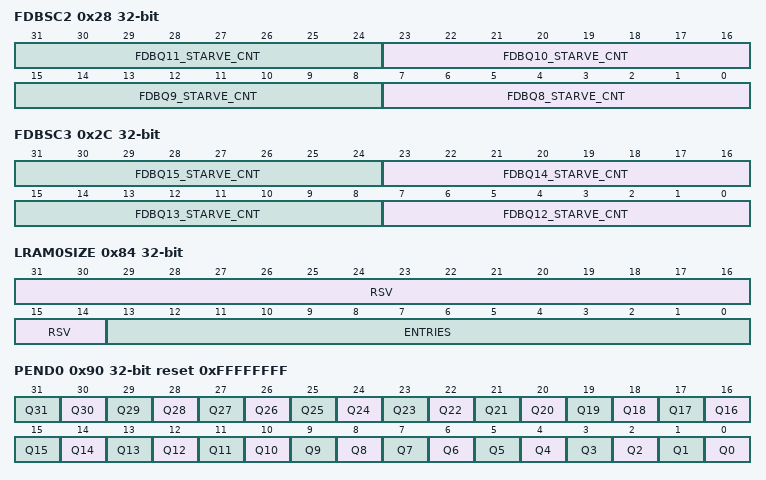
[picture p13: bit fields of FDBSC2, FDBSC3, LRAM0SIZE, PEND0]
  0x28 FDBSC2 ro — Queue Manager Free Descriptor/Buffer Starvation Count Register 2
    [8n-57:8n-64] FDBQ{n}_STARVE_CNT (n=8..11) — This field increments each time Free Descriptor/Buffer Read Queue {n} is read while empty. This field is cleared on read.
  0x2C FDBSC3 ro — Queue Manager Free Descriptor/Buffer Starvation Count Register 3
    [8n-89:8n-96] FDBQ{n}_STARVE_CNT (n=12..15) — This field increments each time Free Descriptor/Buffer Read Queue {n} is read while empty. This field is cleared on read.
  0x80 LRAM0BASE — Linking RAM Region 0 Base Address
    [31:0] REGION0_BASE
  0x84 LRAM0SIZE access per field — Linking RAM Region 0 Size
    [31:14] RSV ro — Reserved
    [13:0] ENTRIES rw — This field indicates the number of entries that are contained in the linking RAM region 0. A descriptor with index less than Region 0 Size value has its linking location in Region 0. A descriptor with index greater than region 0 size has its linking location in region 1. The queue manager will add the index (left shifted by 2 bits) to the appropriate RegionX_base_addr to get an absolute 32-bit address to the linking location for the descriptor.
  0x88 LRAM1BASE — Linking RAM 1 Base Address
    [31:0] REGION1_BASE
  0x90 PEND0 ro reset 0xFFFFFFFF — Queue Manager Queue Pending Register 0
    [n] Q{n} (n=0..31) — Q{n} Pending Status
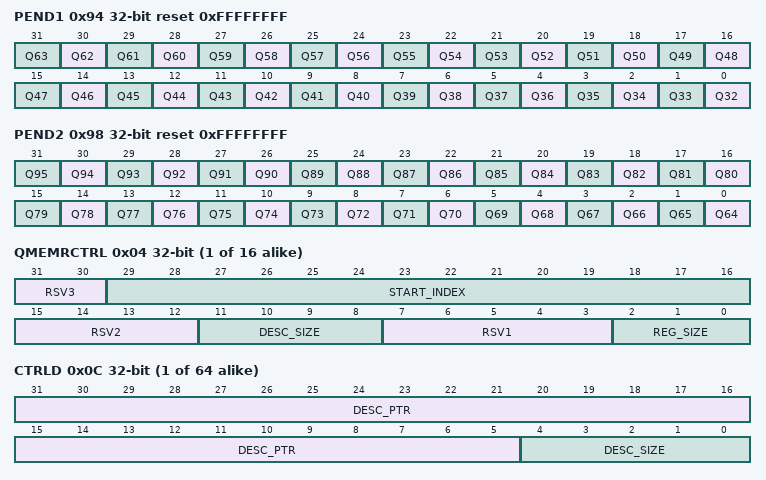
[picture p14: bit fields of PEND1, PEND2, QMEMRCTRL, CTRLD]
  0x94 PEND1 ro reset 0xFFFFFFFF — Queue Manager Queue Pending Register 1
    [n-32] Q{n} (n=32..63) — Q{n} Pending Status
  0x98 PEND2 ro reset 0xFFFFFFFF — Queue Manager Queue Pending Register 2
    [n-64] Q{n} (n=64..95) — Q{n} Pending Status
{0x5000+0x10*i} QMEMREGION[{i}] (i=0..15) group — Queue Manager Descriptor Registers
  0x00 QMEMRBASE — BASE ADDRESS OF MEMORY REGION
    [31:0] REG
  0x04 QMEMRCTRL access per field — MEMORY REGION CONTROL REGISTER
    [31:30] RSV3 ro — RESERVED
    [29:16] START_INDEX rw — This field indicates where in the linking RAM does the descriptor linking information corresponding to memory region R starts.
    [15:12] RSV2 ro — RESERVED
    [11:8] DESC_SIZE rw — Descriptor Size - This field indicates the size of each descriptor in the memory region. It is an encoded value that specifies the descriptor size as 2^(5+DESCSIZE) number of bytes. Valid values are 0 to 8.
    [7:3] RSV1 ro — RESERVED
    [2:0] REG_SIZE rw — This field indicates the size of the memory region (in terms of number of descriptors). It is an encoded value that specifies region size as 2^(5+REGSIZE) number of descriptors
{0x6000+0x10*i} QCTRL[{i}] (i=0..63) group — Queue Manager Queue Control Registers
  0x0C CTRLD — QUEUE N Control Register A
    [31:5] DESC_PTR — Descriptor Pointer - Aligned to a 32-bit boundary. Reads return zero if the queue is empty and a descriptor address when the queue is not empty
    [4:0] DESC_SIZE — Descriptor Size. Number of 4 byte words minus 6; value 0 representing 24 bytes, 1 representing 28 bytes... 31 representing 148 bytes.
{0x6800+0x10*i} QSTAT[{i}] (i=0..63) group — Queue Manager Queue Status Registers
  0x00 QSTATA ro — QUEUE N Status Register A
    [31:14] RSV — RESERVED
    [13:0] QUEUE_ENTRY_COUNT
  0x04 QSTATB ro — QUEUE N Status Register B
    [31:28] RSV — RESERVED
    [27:0] QUEUE_BYTE_COUNT — Queue Total Byte Count
  0x08 QSTATC access per field — QUEUE N Status Register C
    [31:14] RSV rw — RESERVED
    [13:0] PACKET_SIZE ro — Head Element Packet Size
